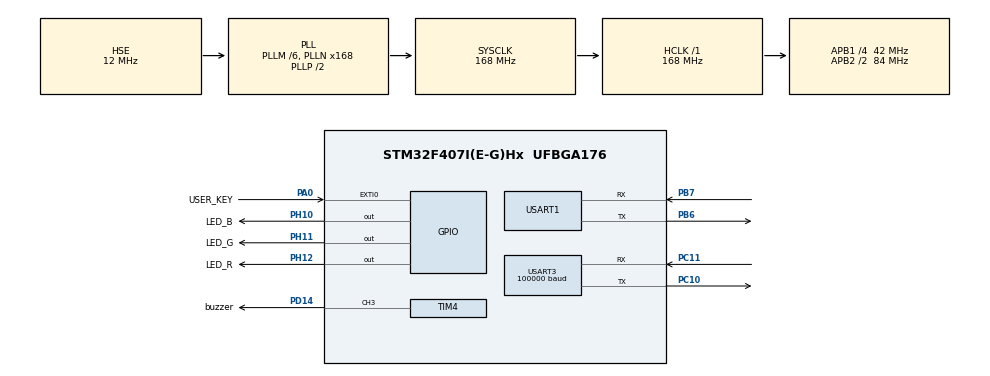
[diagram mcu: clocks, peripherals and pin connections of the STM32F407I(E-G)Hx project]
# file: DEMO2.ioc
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Dma.Request0=USART1_TX
Dma.Request1=USART3_RX
Dma.USART1_TX.0.Direction=DMA_MEMORY_TO_PERIPH
Dma.USART1_TX.0.FIFOMode=DMA_FIFOMODE_DISABLE
Dma.USART1_TX.0.Instance=DMA2_Stream7
Dma.USART1_TX.0.MemDataAlignment=DMA_MDATAALIGN_BYTE
Dma.USART1_TX.0.MemInc=DMA_MINC_ENABLE
Dma.USART1_TX.0.Mode=DMA_NORMAL
Dma.USART1_TX.0.PeriphDataAlignment=DMA_PDATAALIGN_BYTE
Dma.USART1_TX.0.PeriphInc=DMA_PINC_DISABLE
Dma.USART1_TX.0.Priority=DMA_PRIORITY_VERY_HIGH
Dma.USART3_RX.1.Direction=DMA_PERIPH_TO_MEMORY
Dma.USART3_RX.1.FIFOMode=DMA_FIFOMODE_DISABLE
Dma.USART3_RX.1.Instance=DMA1_Stream1
Dma.USART3_RX.1.MemDataAlignment=DMA_MDATAALIGN_BYTE
Dma.USART3_RX.1.MemInc=DMA_MINC_ENABLE
Dma.USART3_RX.1.Mode=DMA_NORMAL
Dma.USART3_RX.1.PeriphDataAlignment=DMA_PDATAALIGN_BYTE
Dma.USART3_RX.1.PeriphInc=DMA_PINC_DISABLE
Dma.USART3_RX.1.Priority=DMA_PRIORITY_VERY_HIGH
Mcu.Family=STM32F4
Mcu.Name=STM32F407I(E-G)Hx
Mcu.Package=UFBGA176
NVIC.DMA1_Stream1_IRQn=true\:0\:0\:false\:false\:true\:false\:true
NVIC.DMA2_Stream7_IRQn=true\:0\:0\:false\:false\:true\:false\:true
NVIC.EXTI0_IRQn=true\:0\:0\:false\:false\:true\:true\:true
NVIC.PriorityGroup=NVIC_PRIORITYGROUP_4
NVIC.TIM1_UP_TIM10_IRQn=true\:0\:0\:false\:false\:true\:true\:true
NVIC.USART1_IRQn=true\:0\:0\:false\:false\:true\:true\:true
PA0-WKUP.GPIO_Label=USER_KEY
PA0-WKUP.GPIO_ModeDefaultEXTI=GPIO_MODE_IT_RISING_FALLING
PA0-WKUP.GPIO_PuPd=GPIO_PULLUP
PA0-WKUP.Signal=GPXTI0
PA13.Mode=Serial_Wire
PA13.Signal=SYS_JTMS-SWDIO
PA14.Mode=Serial_Wire
PA14.Signal=SYS_JTCK-SWCLK
PB6.Mode=Asynchronous
PB6.Signal=USART1_TX
PB7.Mode=Asynchronous
PB7.Signal=USART1_RX
PC10.Mode=Asynchronous
PC10.Signal=USART3_TX
PC11.Mode=Asynchronous
PC11.Signal=USART3_RX
PD14.GPIO_Label=buzzer
PD14.Signal=S_TIM4_CH3
PH0-OSC_IN.Mode=HSE-External-Oscillator
PH0-OSC_IN.Signal=RCC_OSC_IN
PH1-OSC_OUT.Mode=HSE-External-Oscillator
PH1-OSC_OUT.Signal=RCC_OSC_OUT
PH10.GPIO_Label=LED_B
PH10.Signal=GPIO_Output
PH11.GPIO_Label=LED_G
PH11.Signal=GPIO_Output
PH12.GPIO_Label=LED_R
PH12.Signal=GPIO_Output
ProjectManager.HeapSize=0x200
ProjectManager.StackSize=0x400
ProjectManager.TargetToolchain=SW4STM32
RCC.48MHZClocksFreq_Value=84000000
RCC.AHBFreq_Value=168000000
RCC.APB1CLKDivider=RCC_HCLK_DIV4
RCC.APB1Freq_Value=42000000
RCC.APB1TimFreq_Value=84000000
RCC.APB2CLKDivider=RCC_HCLK_DIV2
RCC.APB2Freq_Value=84000000
RCC.APB2TimFreq_Value=168000000
RCC.CortexFreq_Value=168000000
RCC.HCLKFreq_Value=168000000
RCC.HSE_VALUE=12000000
RCC.HSI_VALUE=16000000
RCC.LSE_VALUE=32768
RCC.PLLM=6
RCC.PLLN=168
RCC.PLLSourceVirtual=RCC_PLLSOURCE_HSE
RCC.SYSCLKFreq_VALUE=168000000
RCC.SYSCLKSource=RCC_SYSCLKSOURCE_PLLCLK
RCC.VCOOutputFreq_Value=336000000
SH.S_TIM4_CH3.0=TIM4_CH3,PWM Generation3 CH3
TIM1.Period=4999
TIM1.Prescaler=16799
TIM4.Channel-PWM\ Generation3\ CH3=TIM_CHANNEL_3
TIM4.Period=20999
USART1.VirtualMode=VM_ASYNC
USART3.BaudRate=100000
USART3.VirtualMode=VM_ASYNC
VP_TIM1_VS_ClockSourceINT.Mode=Internal
VP_TIM4_VS_ClockSourceINT.Mode=Internal
board=custom

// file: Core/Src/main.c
/* USER CODE BEGIN Header */
/**
  ******************************************************************************
  * @file           : main.c
  * @brief          : Main program body
  ******************************************************************************
  * @attention
  *
  * <h2><center>&copy; Copyright (c) 2020 STMicroelectronics.
  * All rights reserved.</center></h2>
  *
  * This software component is licensed by ST under BSD 3-Clause license,
  * the "License"; You may not use this file except in compliance with the
  * License. You may obtain a copy of the License at:
  *                        opensource.org/licenses/BSD-3-Clause
  *
  ******************************************************************************
  */
/* USER CODE END Header */
#include "main.h"
#include "dma.h"
#include "tim.h"
#include "usart.h"
#include "gpio.h"
#include "../Board_task/bsp_rc.h"

void SystemClock_Config(void);

int main(void) {

    /* MCU Configuration--------------------------------------------------------*/

    /* Reset of all peripherals, Initializes the Flash interface and the Systick. */
    HAL_Init();

    /* Configure the system clock */
    SystemClock_Config();

    /* Initialize all configured peripherals */
    MX_GPIO_Init();
    MX_DMA_Init();
    MX_TIM1_Init();
    MX_TIM4_Init();
    MX_USART1_UART_Init();
    MX_USART3_UART_Init();
    /* USER CODE BEGIN 2 */
    HAL_TIM_Base_Start(&htim1);
//    HAL_TIM_Base_Start_IT(&htim1);
    HAL_TIM_Base_Start(&htim4);
    HAL_TIM_PWM_Start(&htim4, TIM_CHANNEL_3);
    /* USER CODE END 2 */

    /* Infinite loop */
    while (1) {

    }
}

void SystemClock_Config(void) {
    RCC_OscInitTypeDef RCC_OscInitStruct = {0};
    RCC_ClkInitTypeDef RCC_ClkInitStruct = {0};

    /** Configure the main internal regulator output voltage
    */
    __HAL_RCC_PWR_CLK_ENABLE();
    __HAL_PWR_VOLTAGESCALING_CONFIG(PWR_REGULATOR_VOLTAGE_SCALE1);
    /** Initializes the RCC Oscillators according to the specified parameters
    * in the RCC_OscInitTypeDef structure.
    */
    RCC_OscInitStruct.OscillatorType = RCC_OSCILLATORTYPE_HSE;
    RCC_OscInitStruct.HSEState = RCC_HSE_ON;
    RCC_OscInitStruct.PLL.PLLState = RCC_PLL_ON;
    RCC_OscInitStruct.PLL.PLLSource = RCC_PLLSOURCE_HSE;
    RCC_OscInitStruct.PLL.PLLM = 6;
    RCC_OscInitStruct.PLL.PLLN = 168;
    RCC_OscInitStruct.PLL.PLLP = RCC_PLLP_DIV2;
    RCC_OscInitStruct.PLL.PLLQ = 4;
    if (HAL_RCC_OscConfig(&RCC_OscInitStruct) != HAL_OK) {
        Error_Handler();
    }
    /** Initializes the CPU, AHB and APB buses clocks
    */
    RCC_ClkInitStruct.ClockType = RCC_CLOCKTYPE_HCLK | RCC_CLOCKTYPE_SYSCLK
                                  | RCC_CLOCKTYPE_PCLK1 | RCC_CLOCKTYPE_PCLK2;
    RCC_ClkInitStruct.SYSCLKSource = RCC_SYSCLKSOURCE_PLLCLK;
    RCC_ClkInitStruct.AHBCLKDivider = RCC_SYSCLK_DIV1;
    RCC_ClkInitStruct.APB1CLKDivider = RCC_HCLK_DIV4;
    RCC_ClkInitStruct.APB2CLKDivider = RCC_HCLK_DIV2;

    if (HAL_RCC_ClockConfig(&RCC_ClkInitStruct, FLASH_LATENCY_5) != HAL_OK) {
        Error_Handler();
    }
}

void Error_Handler(void) {
}

/************************ (C) COPYRIGHT STMicroelectronics *****END OF FILE****/
